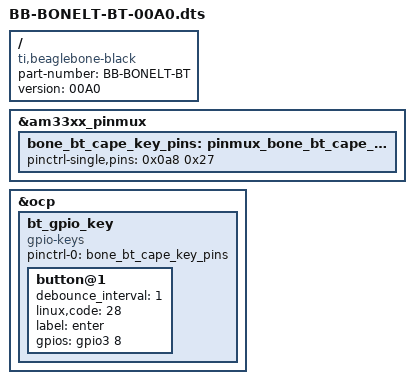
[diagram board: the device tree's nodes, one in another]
/*
 * Copyright (C) 2013 CircuitCo
 *
 * This program is free software; you can redistribute it and/or modify
 * it under the terms of the GNU General Public License version 2 as
 * published by the Free Software Foundation.
 */
/dts-v1/;
/plugin/;

/ {
	compatible = "ti,beaglebone-black";

	/* identification */
	part-number = "BB-BONELT-BT";
	version = "00A0";

	fragment@0 {
		target = <&am33xx_pinmux>;
		__overlay__ {

			bone_bt_cape_key_pins: pinmux_bone_bt_cape_key_pins {
				pinctrl-single,pins = <
					0x0a8 0x27 /* P8.43 lcd_data2.gpio2[8]    */
				>;
			};
		};
	};

	fragment@1 {
		target = <&ocp>;
		__overlay__ {
			bt_gpio_key {
				compatible = "gpio-keys";
				pinctrl-names = "default";
				pinctrl-0 = <&bone_bt_cape_key_pins>;

				#address-cells = <1>;
				#size-cells = <0>;

				button@1 {
					debounce_interval = <1>;
					linux,code = <28>;
					label = "enter";
					gpios = <&gpio3 8 0x0>;
				};
			};
		};
	};
};
